# psc3_p8_ppca register map
Vendor: Infineon Technologies; Series: PSC3_P8; File version: 1.0
CPU: CM33 r0p1, little endian, MPU, FPU, DSP, VTOR, 3 interrupt priority bits, 143 interrupts
Registers are 32-bit, read-write, reset 0x0 unless marked. A register's access mark holds for its fields unless they carry their own. Offsets are from the block's base; [hi:lo] are bit positions; lines under a group give offsets from that group; {n}, {i} and the like mark numbered series; 'fields as' and 'values as' point back to an identical list; <NAME> marks a mode.

## PPCA_CLB
Base 0x43530000
0x00 CTRL
  [31] EN — Enable/Disable CLB block 1 = CLB Enable (all AHB CLB registers are accessible) 0 = CLB Disable (only CTRL register is accessible)
  [9] DEBUG_FREEZE_EN — Debug CLB with freezing the output (safe state): 1 = Debugging mode (step-by-step debugging) 0 = Non-debugging mode
  [8] MACO_SEL — Select CLB output: 1 = line, line_compl and monitor of MACO 0 = line, line_compl and monitor of DICO
  [5:0] TRIG_IN ro — User Input Bits: reflects status of TRIG_IN bus
0x2000 DICO group
  0x00 CTRL
    [31] EN — 1 = DICO Enable 0 = DICO Disable
    [17:8] USER_BITS
    [4] PE_EN — 1 = Phase Enabler (PE) Enable 0 = PE Disable
    [2] EN_PH3 — Phase3 enable: 1 = Enable 0 = Disable
    [1] EN_PH2 — Phase2 enable: 1 = Enable 0 = Disable
    [0] EN_PH1 — Phase1 enable: 1 = Enable 0 = Disable
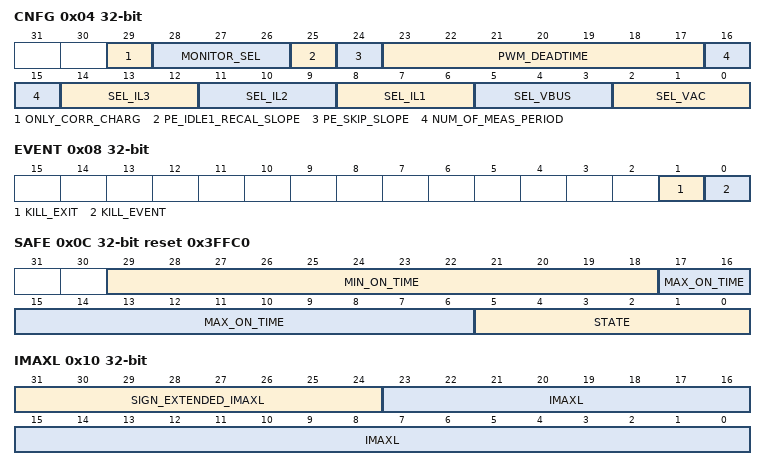
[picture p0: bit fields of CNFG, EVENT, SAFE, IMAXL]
  0x04 CNFG
    [29] ONLY_CORR_CHARG — Correct only the IMIN or IMAX reached during the charging phase. Specifically, correct IMAX when Vac < 0 and IMIN when Vac < 0.
    [28:26] MONITOR_SEL — Select signals to monitor: 0: PCO_0 signals 1: PCO_1 signals 2: PCO_2 signals 3: PE signals 4: PS signals
    [25] PE_IDLE1_RECAL_SLOPE — PE: Recalculate slopes when in the state of PE_IDLE1
    [24] PE_SKIP_SLOPE — PE: Skip FSM states for calculating UP and DOWN slope
    [23:17] PWM_DEADTIME — Select ADC FILT out as input to IL3
    [16:15] NUM_OF_MEAS_PERIOD — Configure Number of Period to be measured: 0: Single Period 1: Two periods 2: Three periods 3: Four periods
    [14:12] SEL_IL3 — Select ADC FILT out as input to IL3
    [11:9] SEL_IL2 — Select ADC FILT out as input to IL2
    [8:6] SEL_IL1 — Select ADC FILT out as input to IL1
    [5:3] SEL_VBUS — Select ADC FILT out as input to VBUS
    [2:0] SEL_VAC — Select ADC FILT out as input to VAC
  0x08 EVENT
    [1] KILL_EXIT write-1-sets — Exit the kill event. KILL_EVENTfrom CPU or EPU has to be de-asserted before or meanwhile.
    [0] KILL_EVENT — Transition to safe state to kill DICO.
  0x0C SAFE reset 0x3FFC0
    [29:18] MIN_ON_TIME — Minimum on-time, enables PWM switching when reached. The counting frequency is equal to one quarter of the system clock.
    [17:6] MAX_ON_TIME — Maximum on-time, forces PWM switching when reached. The counting frequency is equal to one quarter of the system clock.
    [5:0] STATE — Safe state of DICO output.
  0x10 IMAXL
    [31:24] SIGN_EXTENDED_IMAXL ro — IMAXL sign extended
    [23:0] IMAXL — Configure the maximum current: IMAX_ANA * L * F * ADC_GAIN
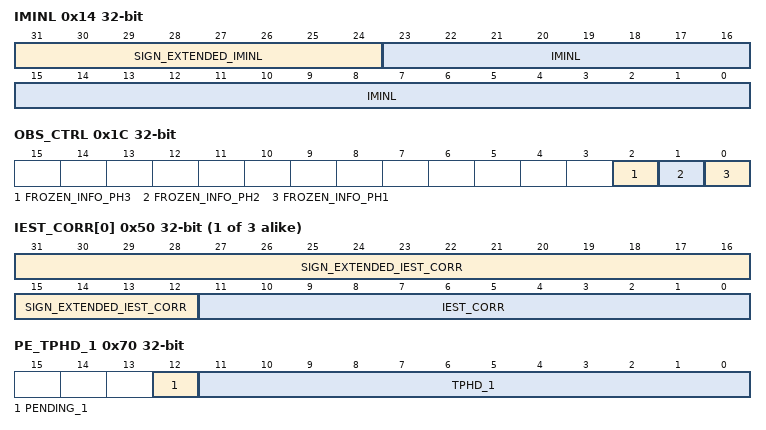
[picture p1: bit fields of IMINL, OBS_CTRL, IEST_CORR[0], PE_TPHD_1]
  0x14 IMINL
    [31:24] SIGN_EXTENDED_IMINL ro — IMINL sign extended
    [23:0] IMINL — Configure the minimum current: IMIN_ANA * L * F * ADC_GAIN
  0x18 VAC_POL
    [1:0] POL — Configure the Polarity of VAC. 0:NEG, 1: ZERO, 2:POS.
  0x1C OBS_CTRL
    [2] FROZEN_INFO_PH3 — Frozen Observer computed Info of Phase3: 1 = Frozen 0 = Unfrozen
    [1] FROZEN_INFO_PH2 — Frozen Observer computed Info of Phase2: 1 = Frozen 0 = Unfrozen
    [0] FROZEN_INFO_PH1 — Frozen Observer computed Info of Phase1: 1 = Frozen 0 = Unfrozen
  {0x20+4j} PERIOD_MEAS[{j}] (j=0..2) ro
    [11:0] PERIOD — Report Measured interval time, related to NUM_OF_MEAS_PERIOD in CNFG.
  {0x30+4j} IEST_IND_ACCU[{j}] (j=0..2) ro
    [31:0] IEST_IND_ACCU — Register Reporting the accumulated estimated current
  {0x40+4j} IL_ACCU[{j}] (j=0..2) ro
    [31:0] IL_ACCU — Register Reporting the accumulated sensored inductor current (24bit registers signed extended)
  {0x50+4j} IEST_CORR[{j}] (j=0..2)
    [31:12] SIGN_EXTENDED_IEST_CORR ro — Correction Sign extended
    [11:0] IEST_CORR — Configure the correction for adjusting the estimated current
  0x60 PE_IMINL ro — IMINL for Up and Down Slope
    [31:0] PE_IMINL — Instant IMINL for calculating up and down slope (24bit registers signed extended)
  0x64 PE_IMAXL ro — IMAXL for Up and Down Slope
    [31:0] PE_IMAXL — Instant IMAXL for calculating up and down slope (24bit registers signed extended)
  0x68 PE_UP_COUNT ro — UP Count Register for Up and Down Slope
    [11:0] UP_COUNT — Count of charging phase (UP).
  0x6C PE_DN_COUNT ro — DOWN Count Register for Up and Down Slope
    [11:0] DOWN_COUNT — Count of discharging phase (DOWN)
  0x70 PE_TPHD_1 — TPHD Value (PCO_1) Register for PE
    [12] PENDING_1 write-1-sets — Pending bit for PE_TPHD_1
    [11:0] TPHD_1 — TPHD Value for activating PCO_1
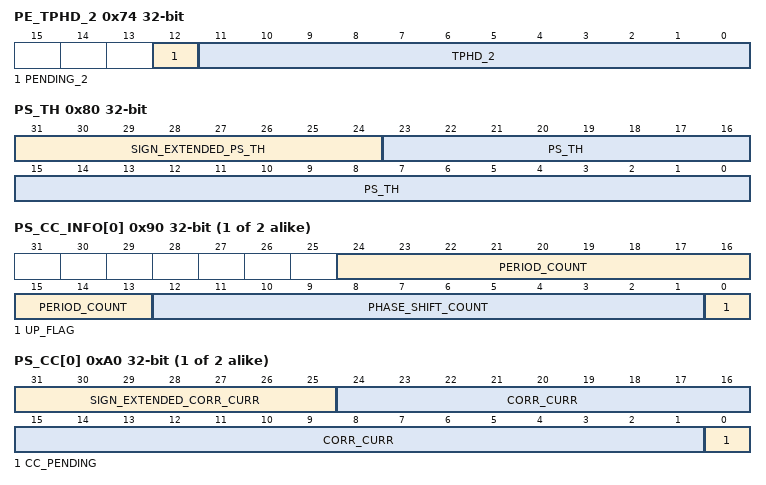
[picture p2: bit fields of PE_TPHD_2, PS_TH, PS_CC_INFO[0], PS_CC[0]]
  0x74 PE_TPHD_2 — TPHD Value (PCO_2) Register for PE
    [12] PENDING_2 write-1-sets — Pending bit for PE_TPHD_2
    [11:0] TPHD_2 — TPHD Value for activating PCO_2
  0x80 PS_TH — Threshold Current multiplied by Inductance Register for PS
    [31:24] SIGN_EXTENDED_PS_TH ro — Threshold for the comparator in Phase Synchronizer (PS) sign extended
    [23:0] PS_TH — Threshold for the comparator in Phase Synchronizer (PS).
  {0x90+4j} PS_CC_INFO[{j}] (j=0..1) ro — IMINL/IMAXL Correction Information Register for PS
    [24:13] PERIOD_COUNT — Count of switch period
    [12:1] PHASE_SHIFT_COUNT — Count of phase shift
    [0] UP_FLAG — Indicates the phase is UP or DOWN
  {0xA0+4j} PS_CC[{j}] (j=0..1) — Correction term of IMINL/IMAXL Register for PS
    [31:25] SIGN_EXTENDED_CORR_CURR ro — Correction term of IMINL and IMAXL for DICO Sign extended
    [24:1] CORR_CURR — Correction term of IMINL and IMAXL for DICO
    [0] CC_PENDING write-1-sets — Pending bit for CORR_CURR
  0xB0 INTR — Interrupt Request Register
    [7:0] DICO_INTR write-1-clears — Interrupt requests of DICO error correction, PE TPHD calculation and PS IMIN/IMAX correction. Details of bit field: 7: PCO_2, 6: PCO_1, 5: PCO_0, 4: PE_SCE2, 3: PE_SCE1, 2: PE_USI, 1: PS_1, 0: PS_0
  0xB4 INTR_SET — Interrupt Set Request Register
    [7:0] DICO_INTR_SET write-1-sets — Write INTR_SET field with '1' to set corresponding INTR field. When read, this register reflects the interrupt request register. That is the INTR register.
  0xB8 INTR_MASK — Interrupt Mask Register
    [7:0] DICO_INTR_MASK — Mask for corresponding field in INTR register.
  0xBC INTR_MASKED ro — Interrupt Masked Register
    [7:0] DICO_INTR_MASKED — Logical AND of corresponding interrupt request (INTR) and mask fields (INTR_MASK).
  {0xC0+4j} PCO_CORR_IEST[{j}] (j=0..2) ro
    [31:0] CORR_IEST — Register Reporting the corrected estimated current (24bit registers signed extended)
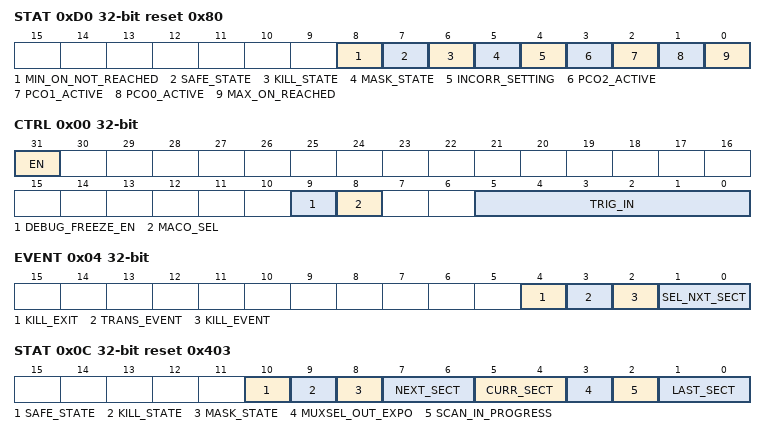
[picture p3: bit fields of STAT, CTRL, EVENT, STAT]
  0xD0 STAT reset 0x80
    [8] MIN_ON_NOT_REACHED write-1-clears — Report minimum on time not reached when PWM modulator FSM state is ready to transit SW write 1 to clear this bit
    [7] SAFE_STATE ro — Report safe state of DICO
    [6] KILL_STATE ro — Report kill state of DICO
    [5] MASK_STATE ro — Report mask state of DICO
    [4] INCORR_SETTING ro — Report incorrect setting of DICO
    [3] PCO2_ACTIVE ro — Report active state of PCO2
    [2] PCO1_ACTIVE ro — Report active state of PCO1
    [1] PCO0_ACTIVE ro — Report active state of PCO0
    [0] MAX_ON_REACHED write-1-clears — Report maximum on time reached SW write 1 to clear this bit
0x4000 MACO group
  0x00 CTRL
    [31] EN — 1 = MACO Enable 0 = MACO Disable
    [12] MONITOR_SEL — Select signals to monitor: 0 = pattern (2-bit), row (5-bit), counter_LSB (1-bit) 1 = counter (8-bit)
    [5] MACO_FUNC — Function of MACO 0 = MACO is used for Matrix Converter 1 = MACO is used for Trajectory Control
    [4] EN_AUTO_TRANSITION — Enable/disable Auto Transition Table selection: 0 = manual (by fw or by external input event) 1 = automatic
    [3] WAIT_FOR_TRIGGER — Select start mode: 0 = start with enable bit 1 = wait for trigger CLB_TRIG_IN[4] before start (after enable has been set)
    [2] MUXSEL_OUT_SYNC_BYPASS — Select between synchronous or asynchronous release of generated MUXSEL_OUT: 0 = asynchrnous 1 = synchronous to CLB_TRIG_IN[3]
    [1] MUXSEL_IN_SRC_SEL — Select MUSEL_IN input source: 0 = internal 1 = external (CLB_TRIG_IN[2])
    [0] FW_MUXSEL_IN — Set FW_MUXSEL_IN internal source
  0x04 EVENT
    [4] KILL_EXIT write-1-sets — Exit the kill event. KILL_EVENTfrom CPU or EPU has to be de-asserted before or meanwhile.
    [3] TRANS_EVENT write-1-sets — Transition to Next/Previous Pattern.
    [2] KILL_EVENT — Transition to safe state to kill MACO.
    [1:0] SEL_NXT_SECT — Select NEXT pattern to be scanned. The field will be evaluated at the end of the scan pattern. If it will be different from before, then the scan will start from row 0: 0 = Select Current Sector 1 = Select Next Sector 2 = Select Previous Sector
  0x0C STAT ro reset 0x403
    [10] SAFE_STATE — Report safe state of MACO
    [9] KILL_STATE — Report kill state of MACO
    [8] MASK_STATE — Report mask state of MACO
    [7:6] NEXT_SECT — Report the next section to be scanned
    [5:4] CURR_SECT — Report the current scanning section
    [3] MUXSEL_OUT_EXPO — Report Status of exported MUXSEL_OUT
    [2] SCAN_IN_PROGRESS — Report Status Of Scan 0: No Scan (waiting for trigger or for enable) 1: Scan is in progress
    [1:0] LAST_SECT — Report Last Scanned Section 3 = startup table
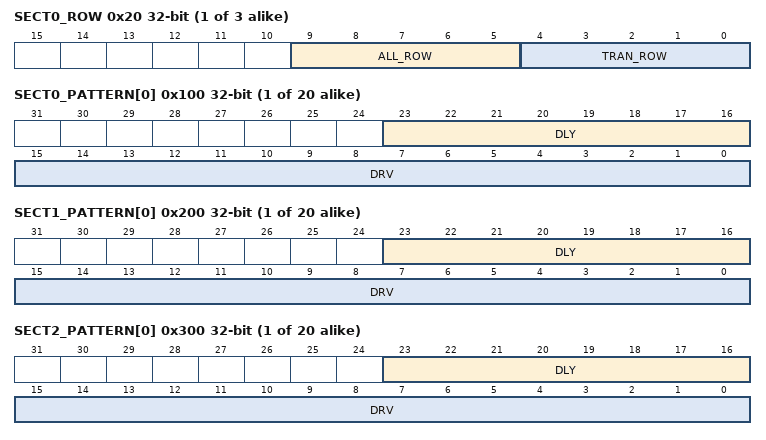
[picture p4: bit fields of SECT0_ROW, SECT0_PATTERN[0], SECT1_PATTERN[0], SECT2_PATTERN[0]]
  {0x20+4j} SECT{j}_ROW (j=0..2)
    [9:5] ALL_ROW — Number of Rows in the entire Table
    [4:0] TRAN_ROW — Number of Rows in Transition Table
  0x30 INTR — Interrupt Request Register
    [0] INTR write-1-clears — Interrupt when a pattern scan is completed
  0x34 INTR_SET — Interrupt Set Request Register
    [0] INTR_SET write-1-sets — Write INTR_SET field with '1' to set corresponding INTR field. When read, this register reflects the interrupt request register. That is the INTR register.
  0x38 INTR_MASK — Interrupt Mask Register
    [0] INTR_MASK — Mask for corresponding field in INTR register.
  0x3C INTR_MASKED ro — Interrupt Masked Register
    [0] INTR_MASKED — Logical AND of corresponding interrupt request (INTR) and mask fields (INTR_MASK).
  {0x100+4j} SECT0_PATTERN[{j}] (j=0..19)
    [23:16] DLY — Configure Scan Pattern Hold Time in clock cycles
    [15:0] DRV — Set Status of Driver Signals controlling switches
  {0x1FC+0x100*j} SECT{j}_SAFE (j=0..2)
    [15:0] DRV — Safe Status of Driver Signals controlling switches
  {0x200+4j} SECT1_PATTERN[{j}] (j=0..19)
    fields as MACO.SECT0_PATTERN[0]
  {0x300+4j} SECT2_PATTERN[{j}] (j=0..19)
    fields as MACO.SECT0_PATTERN[0]
